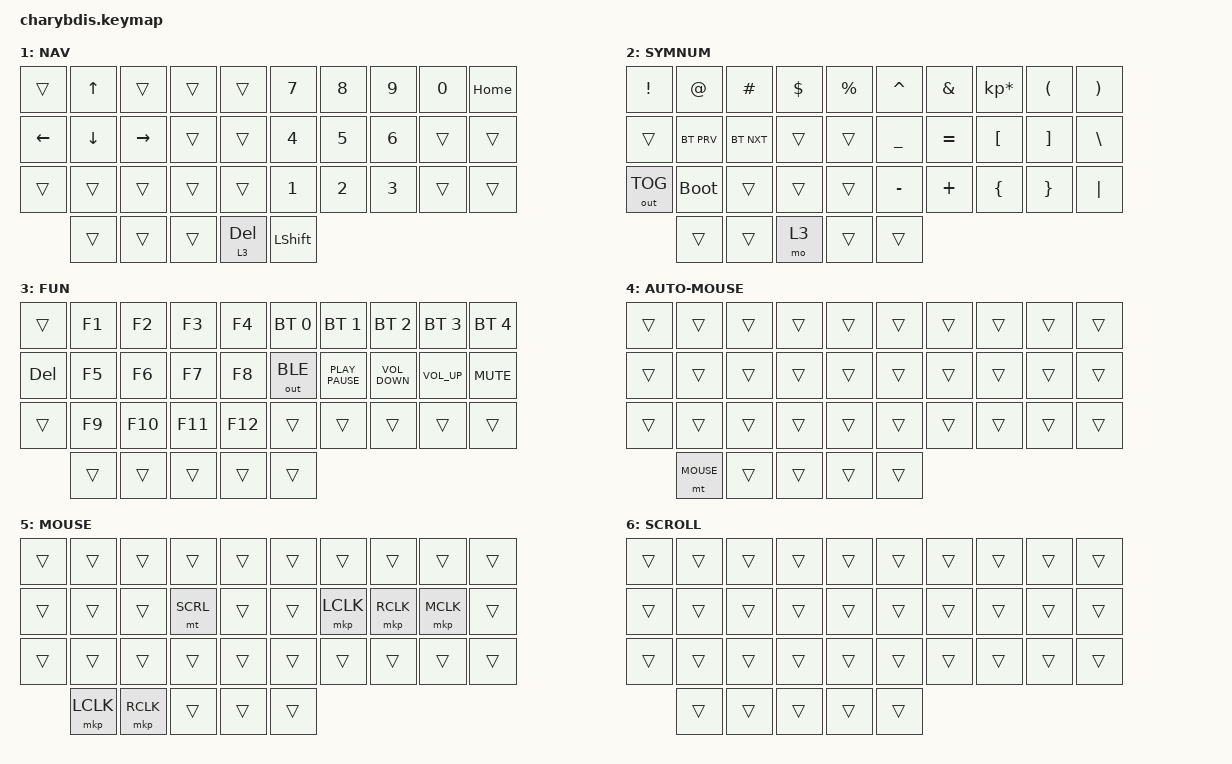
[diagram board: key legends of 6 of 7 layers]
#include <behaviors/mouse_keys.dtsi>
#include <behaviors.dtsi>
#include <dt-bindings/zmk/bt.h>
#include <dt-bindings/zmk/keys.h>
#include <dt-bindings/zmk/mouse.h>
#include <dt-bindings/zmk/outputs.h>

//#include "combos.dtsi"
//#include "behaviors.dtsi"


#define QWERTY_LAYER 0
#define NAV_LAYER 1
#define SYMNUM_LAYER 2
#define FUN_LAYER 3

// Mouse layers must match the layer order below.
#define AUTOMOUSE 4
#define MOUSE 5
#define SCRL 6

// Home row mods macro
#define HRML(k1,k2,k3,k4) &mt LSHFT k1  &mt LCTRL k2  &mt LALT k3  &kp  k4
#define HRMR(k1,k2,k3,k4) &kp k1  &mt RALT k2  &mt RCTRL k3  &mt RSHFT k4

/ {
    
   chosen { zmk,matrix_transform = &default_transform; };
   keymap {
        compatible = "zmk,keymap";

        default_layer {
            bindings = <
        //╭──────────┬──────────┬──────────┬──────────┬──────────╮   ╭──────────┬──────────┬──────────┬──────────┬──────────╮
        //│  Q       │  W       │  E       │  R       │  T       │   │  Y       │  U       │  I       │  O       │  P       │
            &kp Q      &kp W      &kp E      &kp R      &kp T          &kp Y      &kp U      &kp I      &kp O      &kp P
        //├──────────┼──────────┼──────────┼──────────┼──────────┤   ├──────────┼──────────┼──────────┼──────────┼──────────┤
        //│  A       │  S       │  D       │  F       │  G       │   │  H       │  J       │  K       │  L       │  ;       │
           HRML(A,         S,         D,         F)     &kp G          &kp H     HRMR(J,         K,         L,         SEMI)
        //├──────────┼──────────┼──────────┼──────────┼──────────┤   ├──────────┼──────────┼──────────┼──────────┼──────────┤
        //│  Z       │  X       │  C       │  V       │  B       │   │  N       │  M       │ , <      │ . >      │ ENTER    │
            &kp Z      &kp X      &kp C      &kp V      &kp B          &kp N      &kp M      &kp COMMA  &kp DOT    &kp ENTER
        //╰──────────┴──────────┴──────────┼──────────┼──────────┤   ├──────────┼──────────┼──────────┴──────────┴──────────╯
                                &kp LSHFT  &kp  TAB &kp SPACE          &kp BSPC  &kp TAB
        //                      ╰──────────┴──────────┴──────────╯   ╰──────────┴──────────╯
            >;
        };


        NAV {
            bindings = <
              &trans    &kp UP    &trans     &trans  &trans    &kp N7           &kp N8                &kp N9          &kp N0  &kp HOME
              &kp LEFT  &kp DOWN  &kp RIGHT  &trans  &trans    &kp N4           &kp N5  &kp N6  &trans  &trans
              &trans    &trans    &trans     &trans  &trans    &kp N1           &kp N2                &kp N3          &trans  &trans
                            &trans     &trans  &trans    &lt 3 DELETE  &kp LSHFT
            >;
        };

        SYMNUM {
            bindings = <
&kp EXCL      &kp AT       &kp HASH    &kp DLLR  &kp PRCNT    &kp CARET  &kp AMPS                 &kp KP_MULTIPLY   &kp LPAR              &kp RPAR              
&trans        &bt BT_PRV   &bt BT_NXT  &trans    &trans       &kp UNDER  &kp EQUAL  &kp LBKT  &kp RBKT             &kp BSLH            
&out OUT_TOG  &bootloader  &trans      &trans    &trans       &kp MINUS  &kp PLUS                 &kp LBRC          &kp RBRC              &kp PIPE             
                                       &trans      &trans    &mo 3        &trans     &trans
            >;
        };
 
        FUN {
            bindings = <
&trans   &kp F1  &kp F2   &kp F3   &kp F4     &bt BT_SEL 0  &bt BT_SEL 1      &bt BT_SEL 2       &bt BT_SEL 3     &bt BT_SEL 4  
&kp DEL  &kp F5  &kp F6   &kp F7   &kp F8     &out OUT_BLE  &kp K_PLAY_PAUSE  &kp C_VOLUME_DOWN  &kp C_VOLUME_UP  &kp C_MUTE    
&trans   &kp F9  &kp F10  &kp F11  &kp F12    &trans        &trans            &trans             &trans           &trans       
                         &trans   &trans   &trans     &trans        &trans
            >;
        };

        AUTO-MOUSE {
            bindings = <
              &trans  &trans  &trans     &trans  &trans       &trans  &trans  &trans  &trans  &trans  
              &trans  &trans  &trans     &trans  &trans       &trans  &trans  &trans  &trans  &trans  
              &trans  &trans  &trans     &trans  &trans       &trans  &trans  &trans  &trans  &trans  
                              &mt MOUSE   &trans  &trans       &trans  &trans
            >;
        };

        MOUSE {
            bindings = <
              &trans  &trans  &trans     &trans  &trans       &trans  &trans  &trans  &trans  &trans  
              &trans  &trans  &trans     &mt SCRL  &trans       &trans  &mkp LCLK  &mkp RCLK  &mkp MCLK  &trans  
              &trans  &trans  &trans     &trans  &trans       &trans  &trans  &trans  &trans  &trans  
                        &mkp LCLK   &mkp RCLK  &trans  &trans  &trans
            >;
        };

        SCROLL {
            bindings = <
&trans  &trans  &trans  &trans  &trans    &trans  &trans  &trans  &trans  &trans  
&trans  &trans  &trans  &trans  &trans    &trans  &trans  &trans  &trans  &trans  
&trans  &trans  &trans  &trans  &trans    &trans  &trans  &trans  &trans  &trans  
                        &trans  &trans  &trans    &trans  &trans
            >;
        };
    };
};
